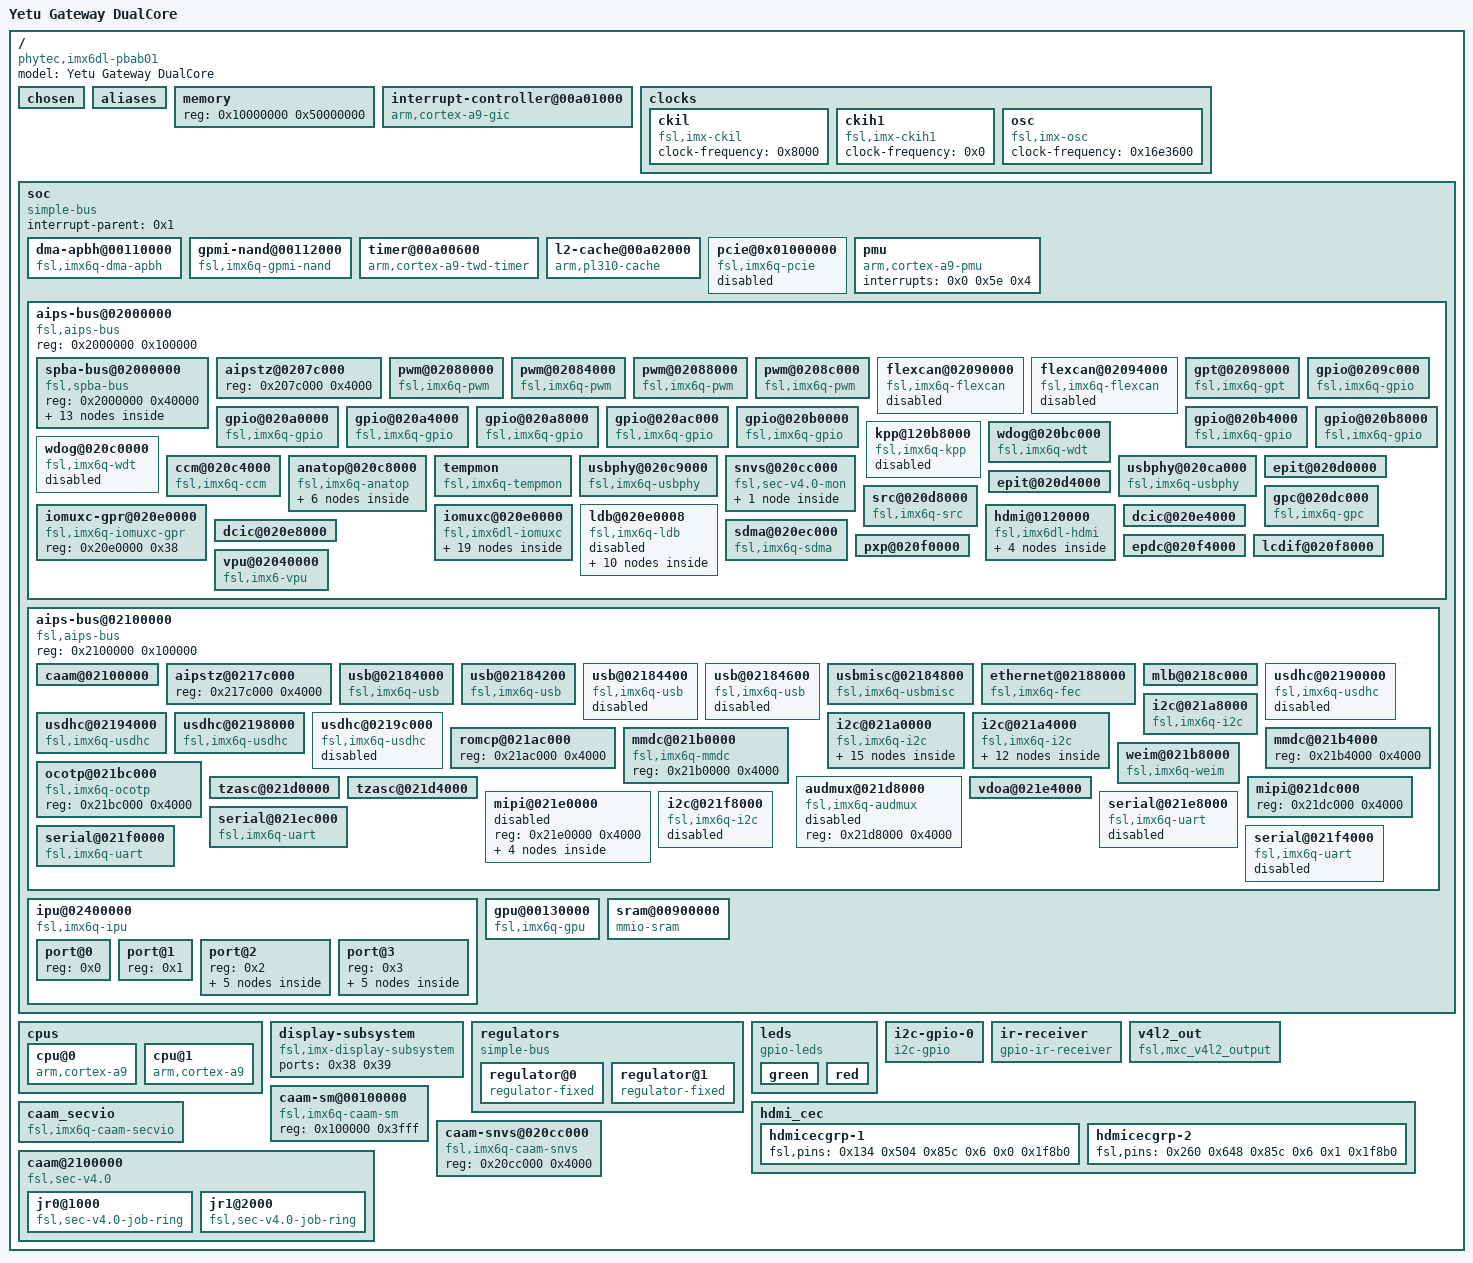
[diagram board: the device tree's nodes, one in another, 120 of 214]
/dts-v1/;

/ {
	#address-cells = <0x1>;
	#size-cells = <0x1>;
	model = "Yetu Gateway DualCore";
	compatible = "phytec,imx6dl-pbab01", "phytec,imx6dl-pfla02", "fsl,imx6dl";

	chosen {
		linux,stdout-path = "/soc/aips-bus@02100000/serial@021f0000";
		bootargs = " cros_debug debug loglevel=7 mem=1024M,0x10000000 drm_kms_helper.edid_firmware=edid/1280x720.bin";
	};

	aliases {
		ethernet0 = "/soc/aips-bus@02100000/ethernet@02188000";
		can0 = "/soc/aips-bus@02000000/flexcan@02090000";
		can1 = "/soc/aips-bus@02000000/flexcan@02094000";
		gpio0 = "/soc/aips-bus@02000000/gpio@0209c000";
		gpio1 = "/soc/aips-bus@02000000/gpio@020a0000";
		gpio2 = "/soc/aips-bus@02000000/gpio@020a4000";
		gpio3 = "/soc/aips-bus@02000000/gpio@020a8000";
		gpio4 = "/soc/aips-bus@02000000/gpio@020ac000";
		gpio5 = "/soc/aips-bus@02000000/gpio@020b0000";
		gpio6 = "/soc/aips-bus@02000000/gpio@020b4000";
		gpio7 = "/soc/aips-bus@02000000/gpio@020b8000";
		i2c0 = "/soc/aips-bus@02100000/i2c@021a0000";
		i2c1 = "/soc/aips-bus@02100000/i2c@021a4000";
		i2c2 = "/soc/aips-bus@02100000/i2c@021a8000";
		mmc0 = "/soc/aips-bus@02100000/usdhc@02190000";
		mmc1 = "/soc/aips-bus@02100000/usdhc@02194000";
		mmc2 = "/soc/aips-bus@02100000/usdhc@02198000";
		mmc3 = "/soc/aips-bus@02100000/usdhc@0219c000";
		serial0 = "/soc/aips-bus@02000000/spba-bus@02000000/serial@02020000";
		serial1 = "/soc/aips-bus@02100000/serial@021e8000";
		serial2 = "/soc/aips-bus@02100000/serial@021ec000";
		serial3 = "/soc/aips-bus@02100000/serial@021f0000";
		serial4 = "/soc/aips-bus@02100000/serial@021f4000";
		spi0 = "/soc/aips-bus@02000000/spba-bus@02000000/ecspi@02008000";
		spi1 = "/soc/aips-bus@02000000/spba-bus@02000000/ecspi@0200c000";
		spi2 = "/soc/aips-bus@02000000/spba-bus@02000000/ecspi@02010000";
		spi3 = "/soc/aips-bus@02000000/spba-bus@02000000/ecspi@02014000";
		usbphy0 = "/soc/aips-bus@02000000/usbphy@020c9000";
		usbphy1 = "/soc/aips-bus@02000000/usbphy@020ca000";
		i2c3 = "/i2c-gpio-0";
	};

	memory {
		device_type = "memory";
		reg = <0x10000000 0x50000000>;
	};

	interrupt-controller@00a01000 {
		compatible = "arm,cortex-a9-gic";
		#interrupt-cells = <0x3>;
		interrupt-controller;
		reg = <0xa01000 0x1000 0xa00100 0x100>;
		linux,phandle = <0x1>;
		phandle = <0x1>;
	};

	clocks {
		#address-cells = <0x1>;
		#size-cells = <0x0>;

		ckil {
			compatible = "fsl,imx-ckil", "fixed-clock";
			#clock-cells = <0x0>;
			clock-frequency = <0x8000>;
		};

		ckih1 {
			compatible = "fsl,imx-ckih1", "fixed-clock";
			#clock-cells = <0x0>;
			clock-frequency = <0x0>;
		};

		osc {
			compatible = "fsl,imx-osc", "fixed-clock";
			#clock-cells = <0x0>;
			clock-frequency = <0x16e3600>;
		};
	};

	soc {
		#address-cells = <0x1>;
		#size-cells = <0x1>;
		compatible = "simple-bus";
		interrupt-parent = <0x1>;
		ranges;

		dma-apbh@00110000 {
			compatible = "fsl,imx6q-dma-apbh", "fsl,imx28-dma-apbh";
			reg = <0x110000 0x2000>;
			interrupts = <0x0 0xd 0x4 0x0 0xd 0x4 0x0 0xd 0x4 0x0 0xd 0x4>;
			interrupt-names = "gpmi0", "gpmi1", "gpmi2", "gpmi3";
			#dma-cells = <0x1>;
			dma-channels = <0x4>;
			clocks = <0x2 0x6a>;
			linux,phandle = <0x3>;
			phandle = <0x3>;
		};

		gpmi-nand@00112000 {
			compatible = "fsl,imx6q-gpmi-nand";
			#address-cells = <0x1>;
			#size-cells = <0x1>;
			reg = <0x112000 0x2000 0x114000 0x2000>;
			reg-names = "gpmi-nand", "bch";
			interrupts = <0x0 0xf 0x4>;
			interrupt-names = "bch";
			clocks = <0x2 0x98 0x2 0x99 0x2 0x97 0x2 0x96 0x2 0x95>;
			clock-names = "gpmi_io", "gpmi_apb", "gpmi_bch", "gpmi_bch_apb", "per1_bch";
			dmas = <0x3 0x0>;
			dma-names = "rx-tx";
			status = "okay";
			pinctrl-names = "default";
			pinctrl-0 = <0x4>;
			nand-on-flash-bbt;
		};

		timer@00a00600 {
			compatible = "arm,cortex-a9-twd-timer";
			reg = <0xa00600 0x20>;
			interrupts = <0x1 0xd 0xf01>;
			clocks = <0x2 0xf>;
		};

		l2-cache@00a02000 {
			compatible = "arm,pl310-cache";
			reg = <0xa02000 0x1000>;
			interrupts = <0x0 0x5c 0x4>;
			cache-unified;
			cache-level = <0x2>;
			arm,tag-latency = <0x4 0x2 0x3>;
			arm,data-latency = <0x4 0x2 0x3>;
			linux,phandle = <0x35>;
			phandle = <0x35>;
		};

		pcie@0x01000000 {
			compatible = "fsl,imx6q-pcie", "snps,dw-pcie";
			reg = <0x1ffc000 0x4000 0x1f00000 0x80000>;
			reg-names = "dbi", "config";
			#address-cells = <0x3>;
			#size-cells = <0x2>;
			device_type = "pci";
			ranges = <0x800 0x0 0x1f00000 0x1f00000 0x0 0x80000 0x81000000 0x0 0x0 0x1f80000 0x0 0x10000 0x82000000 0x0 0x1000000 0x1000000 0x0 0xf00000>;
			num-lanes = <0x1>;
			interrupts = <0x0 0x78 0x4>;
			interrupt-names = "msi";
			#interrupt-cells = <0x1>;
			interrupt-map-mask = <0x0 0x0 0x0 0x7>;
			interrupt-map = <0x0 0x0 0x0 0x1 0x1 0x0 0x7b 0x4 0x0 0x0 0x0 0x2 0x1 0x0 0x7a 0x4 0x0 0x0 0x0 0x3 0x1 0x0 0x79 0x4 0x0 0x0 0x0 0x4 0x1 0x0 0x78 0x4>;
			clocks = <0x2 0x90 0x2 0xce 0x2 0xbd>;
			clock-names = "pcie", "pcie_bus", "pcie_phy";
			status = "disabled";
		};

		pmu {
			compatible = "arm,cortex-a9-pmu";
			interrupts = <0x0 0x5e 0x4>;
		};

		aips-bus@02000000 {
			compatible = "fsl,aips-bus", "simple-bus";
			#address-cells = <0x1>;
			#size-cells = <0x1>;
			reg = <0x2000000 0x100000>;
			ranges;

			spba-bus@02000000 {
				compatible = "fsl,spba-bus", "simple-bus";
				#address-cells = <0x1>;
				#size-cells = <0x1>;
				reg = <0x2000000 0x40000>;
				ranges;

				spdif@02004000 {
					compatible = "fsl,imx35-spdif";
					reg = <0x2004000 0x4000>;
					interrupts = <0x0 0x34 0x4>;
					dmas = <0x5 0xe 0x12 0x0 0x5 0xf 0x12 0x0>;
					dma-names = "rx", "tx";
					clocks = <0x2 0xc5 0x2 0x3 0x2 0xc5 0x2 0x0 0x2 0x0 0x2 0x0 0x2 0x0 0x2 0x0 0x2 0x0>;
					clock-names = "core", "rxtx0", "rxtx1", "rxtx2", "rxtx3", "rxtx4", "rxtx5", "rxtx6", "rxtx7";
					status = "disabled";
				};

				ecspi@02008000 {
					#address-cells = <0x1>;
					#size-cells = <0x0>;
					compatible = "fsl,imx6q-ecspi", "fsl,imx51-ecspi";
					reg = <0x2008000 0x4000>;
					interrupts = <0x0 0x1f 0x4>;
					clocks = <0x2 0x70 0x2 0x70>;
					clock-names = "ipg", "per";
					dmas = <0x5 0x3 0x7 0x1 0x5 0x4 0x7 0x2>;
					dma-names = "rx", "tx";
					status = "disabled";
				};

				ecspi@0200c000 {
					#address-cells = <0x1>;
					#size-cells = <0x0>;
					compatible = "fsl,imx6q-ecspi", "fsl,imx51-ecspi";
					reg = <0x200c000 0x4000>;
					interrupts = <0x0 0x20 0x4>;
					clocks = <0x2 0x71 0x2 0x71>;
					clock-names = "ipg", "per";
					dmas = <0x5 0x5 0x7 0x1 0x5 0x6 0x7 0x2>;
					dma-names = "rx", "tx";
					status = "disabled";
				};

				ecspi@02010000 {
					#address-cells = <0x1>;
					#size-cells = <0x0>;
					compatible = "fsl,imx6q-ecspi", "fsl,imx51-ecspi";
					reg = <0x2010000 0x4000>;
					interrupts = <0x0 0x21 0x4>;
					clocks = <0x2 0x72 0x2 0x72>;
					clock-names = "ipg", "per";
					dmas = <0x5 0x7 0x7 0x1 0x5 0x8 0x7 0x2>;
					dma-names = "rx", "tx";
					status = "okay";
					pinctrl-names = "default";
					pinctrl-0 = <0x6>;
					fsl,spi-num-chipselects = <0x1>;
					cs-gpios = <0x7 0x18 0x0>;

					flash@0 {
						compatible = "m25p80";
						spi-max-frequency = <0x1312d00>;
						reg = <0x0>;
					};
				};

				ecspi@02014000 {
					#address-cells = <0x1>;
					#size-cells = <0x0>;
					compatible = "fsl,imx6q-ecspi", "fsl,imx51-ecspi";
					reg = <0x2014000 0x4000>;
					interrupts = <0x0 0x22 0x4>;
					clocks = <0x2 0x73 0x2 0x73>;
					clock-names = "ipg", "per";
					dmas = <0x5 0x9 0x7 0x1 0x5 0xa 0x7 0x2>;
					dma-names = "rx", "tx";
					status = "disabled";
				};

				serial@02020000 {
					compatible = "fsl,imx6q-uart", "fsl,imx21-uart";
					reg = <0x2020000 0x4000>;
					interrupts = <0x0 0x1a 0x4>;
					clocks = <0x2 0xa0 0x2 0xa1>;
					clock-names = "ipg", "per";
					dmas = <0x5 0x19 0x4 0x0 0x5 0x1a 0x4 0x0>;
					dma-names = "rx", "tx";
					status = "okay";
					pinctrl-names = "default";
					pinctrl-0 = <0x8>;
				};

				esai@02024000 {
					reg = <0x2024000 0x4000>;
					interrupts = <0x0 0x33 0x4>;
				};

				ssi@02028000 {
					#sound-dai-cells = <0x0>;
					compatible = "fsl,imx6q-ssi", "fsl,imx51-ssi";
					reg = <0x2028000 0x4000>;
					interrupts = <0x0 0x2e 0x4>;
					clocks = <0x2 0xb2 0x2 0x9d>;
					clock-names = "ipg", "baud";
					dmas = <0x5 0x25 0x1 0x0 0x5 0x26 0x1 0x0>;
					dma-names = "rx", "tx";
					fsl,fifo-depth = <0xf>;
					status = "disabled";
				};

				ssi@0202c000 {
					#sound-dai-cells = <0x0>;
					compatible = "fsl,imx6q-ssi", "fsl,imx51-ssi";
					reg = <0x202c000 0x4000>;
					interrupts = <0x0 0x2f 0x4>;
					clocks = <0x2 0xb3 0x2 0x9e>;
					clock-names = "ipg", "baud";
					dmas = <0x5 0x29 0x1 0x0 0x5 0x2a 0x1 0x0>;
					dma-names = "rx", "tx";
					fsl,fifo-depth = <0xf>;
					status = "disabled";
				};

				ssi@02030000 {
					#sound-dai-cells = <0x0>;
					compatible = "fsl,imx6q-ssi", "fsl,imx51-ssi";
					reg = <0x2030000 0x4000>;
					interrupts = <0x0 0x30 0x4>;
					clocks = <0x2 0xb4 0x2 0x9f>;
					clock-names = "ipg", "baud";
					dmas = <0x5 0x2d 0x1 0x0 0x5 0x2e 0x1 0x0>;
					dma-names = "rx", "tx";
					fsl,fifo-depth = <0xf>;
					status = "disabled";
				};

				asrc@02034000 {
					reg = <0x2034000 0x4000>;
					interrupts = <0x0 0x32 0x4>;
				};

				spba@0203c000 {
					reg = <0x203c000 0x4000>;
				};
			};

			aipstz@0207c000 {
				reg = <0x207c000 0x4000>;
			};

			pwm@02080000 {
				#pwm-cells = <0x2>;
				compatible = "fsl,imx6q-pwm", "fsl,imx27-pwm";
				reg = <0x2080000 0x4000>;
				interrupts = <0x0 0x53 0x4>;
				clocks = <0x2 0x3e 0x2 0x91>;
				clock-names = "ipg", "per";
			};

			pwm@02084000 {
				#pwm-cells = <0x2>;
				compatible = "fsl,imx6q-pwm", "fsl,imx27-pwm";
				reg = <0x2084000 0x4000>;
				interrupts = <0x0 0x54 0x4>;
				clocks = <0x2 0x3e 0x2 0x92>;
				clock-names = "ipg", "per";
			};

			pwm@02088000 {
				#pwm-cells = <0x2>;
				compatible = "fsl,imx6q-pwm", "fsl,imx27-pwm";
				reg = <0x2088000 0x4000>;
				interrupts = <0x0 0x55 0x4>;
				clocks = <0x2 0x3e 0x2 0x93>;
				clock-names = "ipg", "per";
			};

			pwm@0208c000 {
				#pwm-cells = <0x2>;
				compatible = "fsl,imx6q-pwm", "fsl,imx27-pwm";
				reg = <0x208c000 0x4000>;
				interrupts = <0x0 0x56 0x4>;
				clocks = <0x2 0x3e 0x2 0x94>;
				clock-names = "ipg", "per";
			};

			flexcan@02090000 {
				compatible = "fsl,imx6q-flexcan";
				reg = <0x2090000 0x4000>;
				interrupts = <0x0 0x6e 0x4>;
				clocks = <0x2 0x6c 0x2 0x6d>;
				clock-names = "ipg", "per";
				status = "disabled";
			};

			flexcan@02094000 {
				compatible = "fsl,imx6q-flexcan";
				reg = <0x2094000 0x4000>;
				interrupts = <0x0 0x6f 0x4>;
				clocks = <0x2 0x6e 0x2 0x6f>;
				clock-names = "ipg", "per";
				status = "disabled";
			};

			gpt@02098000 {
				compatible = "fsl,imx6q-gpt", "fsl,imx31-gpt";
				reg = <0x2098000 0x4000>;
				interrupts = <0x0 0x37 0x4>;
				clocks = <0x2 0x77 0x2 0x78 0x2 0xed>;
				clock-names = "ipg", "per", "osc_per";
			};

			gpio@0209c000 {
				compatible = "fsl,imx6q-gpio", "fsl,imx35-gpio";
				reg = <0x209c000 0x4000>;
				interrupts = <0x0 0x42 0x4 0x0 0x43 0x4>;
				gpio-controller;
				#gpio-cells = <0x2>;
				interrupt-controller;
				#interrupt-cells = <0x2>;
				linux,phandle = <0x22>;
				phandle = <0x22>;
			};

			gpio@020a0000 {
				compatible = "fsl,imx6q-gpio", "fsl,imx35-gpio";
				reg = <0x20a0000 0x4000>;
				interrupts = <0x0 0x44 0x4 0x0 0x45 0x4>;
				gpio-controller;
				#gpio-cells = <0x2>;
				interrupt-controller;
				#interrupt-cells = <0x2>;
				linux,phandle = <0x3a>;
				phandle = <0x3a>;
			};

			gpio@020a4000 {
				compatible = "fsl,imx6q-gpio", "fsl,imx35-gpio";
				reg = <0x20a4000 0x4000>;
				interrupts = <0x0 0x46 0x4 0x0 0x47 0x4>;
				gpio-controller;
				#gpio-cells = <0x2>;
				interrupt-controller;
				#interrupt-cells = <0x2>;
				linux,phandle = <0x1f>;
				phandle = <0x1f>;
			};

			gpio@020a8000 {
				compatible = "fsl,imx6q-gpio", "fsl,imx35-gpio";
				reg = <0x20a8000 0x4000>;
				interrupts = <0x0 0x48 0x4 0x0 0x49 0x4>;
				gpio-controller;
				#gpio-cells = <0x2>;
				interrupt-controller;
				#interrupt-cells = <0x2>;
				linux,phandle = <0x7>;
				phandle = <0x7>;
			};

			gpio@020ac000 {
				compatible = "fsl,imx6q-gpio", "fsl,imx35-gpio";
				reg = <0x20ac000 0x4000>;
				interrupts = <0x0 0x4a 0x4 0x0 0x4b 0x4>;
				gpio-controller;
				#gpio-cells = <0x2>;
				interrupt-controller;
				#interrupt-cells = <0x2>;
			};

			gpio@020b0000 {
				compatible = "fsl,imx6q-gpio", "fsl,imx35-gpio";
				reg = <0x20b0000 0x4000>;
				interrupts = <0x0 0x4c 0x4 0x0 0x4d 0x4>;
				gpio-controller;
				#gpio-cells = <0x2>;
				interrupt-controller;
				#interrupt-cells = <0x2>;
			};

			gpio@020b4000 {
				compatible = "fsl,imx6q-gpio", "fsl,imx35-gpio";
				reg = <0x20b4000 0x4000>;
				interrupts = <0x0 0x4e 0x4 0x0 0x4f 0x4>;
				gpio-controller;
				#gpio-cells = <0x2>;
				interrupt-controller;
				#interrupt-cells = <0x2>;
				linux,phandle = <0x27>;
				phandle = <0x27>;
			};

			gpio@020b8000 {
				compatible = "fsl,imx6q-gpio", "fsl,imx35-gpio";
				reg = <0x20b8000 0x4000>;
				gpio-controller;
				#gpio-cells = <0x2>;
			};

			kpp@120b8000 {
				compatible = "fsl,imx6q-kpp", "fsl,imx21-kpp";
				reg = <0x120b8000 0x4000>;
				interrupts = <0x0 0x52 0x4>;
				clocks = <0x2 0x3e>;
				status = "disabled";
			};

			wdog@020bc000 {
				compatible = "fsl,imx6q-wdt", "fsl,imx21-wdt";
				reg = <0x20bc000 0x4000>;
				interrupts = <0x0 0x50 0x4>;
				clocks = <0x2 0x0>;
			};

			wdog@020c0000 {
				compatible = "fsl,imx6q-wdt", "fsl,imx21-wdt";
				reg = <0x20c0000 0x4000>;
				interrupts = <0x0 0x51 0x4>;
				clocks = <0x2 0x0>;
				status = "disabled";
			};

			ccm@020c4000 {
				compatible = "fsl,imx6q-ccm";
				reg = <0x20c4000 0x4000>;
				interrupts = <0x0 0x57 0x4 0x0 0x58 0x4>;
				#clock-cells = <0x1>;
				linux,phandle = <0x2>;
				phandle = <0x2>;
			};

			anatop@020c8000 {
				compatible = "fsl,imx6q-anatop", "syscon", "simple-bus";
				reg = <0x20c8000 0x1000>;
				interrupts = <0x0 0x31 0x4 0x0 0x36 0x4 0x0 0x7f 0x4>;
				linux,phandle = <0x9>;
				phandle = <0x9>;

				regulator-1p1@110 {
					compatible = "fsl,anatop-regulator";
					regulator-name = "vdd1p1";
					regulator-min-microvolt = <0xc3500>;
					regulator-max-microvolt = <0x14fb18>;
					regulator-always-on;
					anatop-reg-offset = <0x110>;
					anatop-vol-bit-shift = <0x8>;
					anatop-vol-bit-width = <0x5>;
					anatop-min-bit-val = <0x4>;
					anatop-min-voltage = <0xc3500>;
					anatop-max-voltage = <0x14fb18>;
				};

				regulator-3p0@120 {
					compatible = "fsl,anatop-regulator";
					regulator-name = "vdd3p0";
					regulator-min-microvolt = <0x2ab980>;
					regulator-max-microvolt = <0x3010b0>;
					regulator-always-on;
					anatop-reg-offset = <0x120>;
					anatop-vol-bit-shift = <0x8>;
					anatop-vol-bit-width = <0x5>;
					anatop-min-bit-val = <0x0>;
					anatop-min-voltage = <0x280de8>;
					anatop-max-voltage = <0x33e140>;
				};

				regulator-2p5@130 {
					compatible = "fsl,anatop-regulator";
					regulator-name = "vdd2p5";
					regulator-min-microvolt = <0x1e8480>;
					regulator-max-microvolt = <0x29f630>;
					regulator-always-on;
					anatop-reg-offset = <0x130>;
					anatop-vol-bit-shift = <0x8>;
					anatop-vol-bit-width = <0x5>;
					anatop-min-bit-val = <0x0>;
					anatop-min-voltage = <0x1e8480>;
					anatop-max-voltage = <0x29f630>;
				};

				regulator-vddcore@140 {
					compatible = "fsl,anatop-regulator";
					regulator-name = "vddarm";
					regulator-min-microvolt = <0xb1008>;
					regulator-max-microvolt = <0x162010>;
					regulator-always-on;
					anatop-reg-offset = <0x140>;
					anatop-vol-bit-shift = <0x0>;
					anatop-vol-bit-width = <0x5>;
					anatop-delay-reg-offset = <0x170>;
					anatop-delay-bit-shift = <0x18>;
					anatop-delay-bit-width = <0x2>;
					anatop-min-bit-val = <0x1>;
					anatop-min-voltage = <0xb1008>;
					anatop-max-voltage = <0x162010>;
					linux,phandle = <0x36>;
					phandle = <0x36>;
				};

				regulator-vddpu@140 {
					compatible = "fsl,anatop-regulator";
					regulator-name = "vddpu";
					regulator-min-microvolt = <0xb1008>;
					regulator-max-microvolt = <0x162010>;
					regulator-always-on;
					anatop-reg-offset = <0x140>;
					anatop-vol-bit-shift = <0x9>;
					anatop-vol-bit-width = <0x5>;
					anatop-delay-reg-offset = <0x170>;
					anatop-delay-bit-shift = <0x1a>;
					anatop-delay-bit-width = <0x2>;
					anatop-min-bit-val = <0x1>;
					anatop-min-voltage = <0xb1008>;
					anatop-max-voltage = <0x162010>;
					linux,phandle = <0x16>;
					phandle = <0x16>;
				};

				regulator-vddsoc@140 {
					compatible = "fsl,anatop-regulator";
					regulator-name = "vddsoc";
					regulator-min-microvolt = <0xb1008>;
					regulator-max-microvolt = <0x162010>;
					regulator-always-on;
					anatop-reg-offset = <0x140>;
					anatop-vol-bit-shift = <0x12>;
					anatop-vol-bit-width = <0x5>;
					anatop-delay-reg-offset = <0x170>;
					anatop-delay-bit-shift = <0x1c>;
					anatop-delay-bit-width = <0x2>;
					anatop-min-bit-val = <0x1>;
					anatop-min-voltage = <0xb1008>;
					anatop-max-voltage = <0x162010>;
					linux,phandle = <0x37>;
					phandle = <0x37>;
				};
			};

			tempmon {
				compatible = "fsl,imx6q-tempmon";
				interrupts = <0x0 0x31 0x4>;
				fsl,tempmon = <0x9>;
				fsl,tempmon-data = <0xa>;
				clocks = <0x2 0xac>;
			};

			usbphy@020c9000 {
				compatible = "fsl,imx6q-usbphy", "fsl,imx23-usbphy";
				reg = <0x20c9000 0x1000>;
				interrupts = <0x0 0x2c 0x4>;
				clocks = <0x2 0xb6>;
				fsl,anatop = <0x9>;
				linux,phandle = <0x17>;
				phandle = <0x17>;
			};

			usbphy@020ca000 {
				compatible = "fsl,imx6q-usbphy", "fsl,imx23-usbphy";
				reg = <0x20ca000 0x1000>;
				interrupts = <0x0 0x2d 0x4>;
				clocks = <0x2 0xb7>;
				fsl,anatop = <0x9>;
				linux,phandle = <0x1b>;
				phandle = <0x1b>;
			};

			snvs@020cc000 {
				compatible = "fsl,sec-v4.0-mon", "simple-bus";
				#address-cells = <0x1>;
				#size-cells = <0x1>;
				ranges = <0x0 0x20cc000 0x4000>;

				snvs-rtc-lp@34 {
					compatible = "fsl,sec-v4.0-mon-rtc-lp";
					reg = <0x34 0x58>;
					interrupts = <0x0 0x13 0x4 0x0 0x14 0x4>;
				};
			};

			epit@020d0000 {
				reg = <0x20d0000 0x4000>;
				interrupts = <0x0 0x38 0x4>;
			};

			epit@020d4000 {
				reg = <0x20d4000 0x4000>;
				interrupts = <0x0 0x39 0x4>;
			};

			src@020d8000 {
				compatible = "fsl,imx6q-src", "fsl,imx51-src";
				reg = <0x20d8000 0x4000>;
				interrupts = <0x0 0x5b 0x4 0x0 0x60 0x4>;
				#reset-cells = <0x1>;
				linux,phandle = <0x15>;
				phandle = <0x15>;
			};

			gpc@020dc000 {
				compatible = "fsl,imx6q-gpc";
				reg = <0x20dc000 0x4000>;
				interrupts = <0x0 0x59 0x4 0x0 0x5a 0x4>;
			};

			iomuxc-gpr@020e0000 {
				compatible = "fsl,imx6q-iomuxc-gpr", "syscon";
				reg = <0x20e0000 0x38>;
				linux,phandle = <0xc>;
				phandle = <0xc>;
			};

			iomuxc@020e0000 {
				compatible = "fsl,imx6dl-iomuxc";
				reg = <0x20e0000 0x4000>;
				pinctrl-names = "default";
				pinctrl-0 = <0xb>;

				imx6q-phytec-pfla02 {

					hdmicecgrp {
						fsl,pins = <0x134 0x504 0x85c 0x6 0x0 0x1f8b0>;
						linux,phandle = <0x11>;
						phandle = <0x11>;
					};

					pinctrli2cgpiogrp {
						fsl,pins = <0x264 0x64c 0x0 0x5 0x0 0x80000000 0x250 0x638 0x0 0x5 0x0 0x80000000>;
						linux,phandle = <0x3b>;
						phandle = <0x3b>;
					};

					hoggrp {
						fsl,pins = <0x160 0x530 0x0 0x5 0x0 0x80000000 0xf4 0x408 0x0 0x5 0x0 0x80000000 0xa0 0x3b4 0x0 0x5 0x0 0x80000000 0x204 0x5d4 0x0 0x5 0x0 0x80000000 0x1d0 0x5a0 0x0 0x5 0x0 0x80000000 0x21c 0x5ec 0x0 0x5 0x0 0x1b0b0 0xa8 0x3bc 0x0 0x5 0x0 0x1b0b0 0x228 0x5f8 0x0 0x5 0x0 0x80000000>;
						linux,phandle = <0xb>;
						phandle = <0xb>;
					};

					ecspi3grp {
						fsl,pins = <0xe0 0x3f4 0x0 0x2 0x0 0x100b1 0xb4 0x3c8 0x0 0x2 0x0 0x100b1 0xb0 0x3c4 0x0 0x2 0x0 0x100b1>;
						linux,phandle = <0x6>;
						phandle = <0x6>;
					};

					enetgrp {
						fsl,pins = <0x1ec 0x5bc 0x810 0x1 0x0 0x1b0b0 0x1e8 0x5b8 0x0 0x1 0x0 0x1b0b0 0x2d8 0x6c0 0x0 0x1 0x0 0x1b0b0 0x2c4 0x6ac 0x0 0x1 0x0 0x1b0b0 0x2c8 0x6b0 0x0 0x1 0x0 0x1b0b0 0x2cc 0x6b4 0x0 0x1 0x0 0x1b0b0 0x2d0 0x6b8 0x0 0x1 0x0 0x1b0b0 0x2d4 0x6bc 0x0 0x1 0x0 0x1b0b0 0x1f0 0x5c0 0x0 0x1 0x0 0x1b0b0 0x2c0 0x6a8 0x814 0x1 0x1 0x1b0b0 0x2ac 0x694 0x818 0x1 0x1 0x1b0b0 0x2b0 0x698 0x81c 0x1 0x1 0x1b0b0 0x2b4 0x69c 0x820 0x1 0x1 0x1b0b0 0x2b8 0x6a0 0x824 0x1 0x1 0x1b0b0 0x2bc 0x6a4 0x828 0x1 0x1 0x1b0b0 0x200 0x5d0 0x0 0x1 0x0 0x1b0b0>;
						linux,phandle = <0x1e>;
						phandle = <0x1e>;
					};

					gpminandgrp {
						fsl,pins = <0x270 0x658 0x0 0x0 0x0 0xb0b1 0x26c 0x654 0x0 0x0 0x0 0xb0b1 0x2a8 0x690 0x0 0x0 0x0 0xb0b1 0x2a4 0x68c 0x0 0x0 0x0 0xb000 0x274 0x65c 0x0 0x0 0x0 0xb0b1 0x278 0x660 0x0 0x0 0x0 0xb0b1 0x33c 0x724 0x0 0x1 0x0 0xb0b1 0x338 0x720 0x0 0x1 0x0 0xb0b1 0x284 0x66c 0x0 0x0 0x0 0xb0b1 0x288 0x670 0x0 0x0 0x0 0xb0b1 0x28c 0x674 0x0 0x0 0x0 0xb0b1 0x290 0x678 0x0 0x0 0x0 0xb0b1 0x294 0x67c 0x0 0x0 0x0 0xb0b1 0x298 0x680 0x0 0x0 0x0 0xb0b1 0x29c 0x684 0x0 0x0 0x0 0xb0b1 0x2a0 0x688 0x0 0x0 0x0 0xb0b1 0x340 0x728 0x0 0x2 0x0 0xb1>;
						linux,phandle = <0x4>;
						phandle = <0x4>;
					};

					i2c1grp {
						fsl,pins = <0x158 0x528 0x868 0x6 0x1 0x4001b8b1 0x174 0x544 0x86c 0x1 0x1 0x4001b8b1>;
						linux,phandle = <0x25>;
						phandle = <0x25>;
					};

					i2c2grp {
						fsl,pins = <0x1cc 0x59c 0x870 0x6 0x0 0x4001b8b1 0x144 0x514 0x874 0x6 0x0 0x4001b8b1>;
						linux,phandle = <0x26>;
						phandle = <0x26>;
					};

					i2c3grp {
						fsl,pins = <0x148 0x518 0x878 0x6 0x0 0x4001b8b1 0x14c 0x51c 0x87c 0x6 0x0 0x4001b8b1>;
						linux,phandle = <0x28>;
						phandle = <0x28>;
					};

					uart3grp {
						fsl,pins = <0x164 0x534 0x0 0x2 0x0 0x1b0b1 0x168 0x538 0x90c 0x2 0x1 0x1b0b1 0x17c 0x54c 0x908 0x4 0x1 0x1b0b1 0x180 0x550 0x0 0x4 0x0 0x1b0b1>;
						linux,phandle = <0x2b>;
						phandle = <0x2b>;
					};

					uart4grp {
						fsl,pins = <0x244 0x62c 0x0 0x4 0x0 0x1b0b1 0x258 0x640 0x914 0x4 0x3 0x1b0b1>;
						linux,phandle = <0x2c>;
						phandle = <0x2c>;
					};

					usbh1grp {
						fsl,pins = <0x20c 0x5dc 0x0 0x6 0x0 0x80000000>;
						linux,phandle = <0x1d>;
						phandle = <0x1d>;
					};

					usbotggrp {
						fsl,pins = <0x210 0x5e0 0x790 0x3 0x1 0x17059 0x254 0x63c 0x920 0x2 0x1 0x1b0b0 0x268 0x650 0x0 0x5 0x0 0x80000000>;
						linux,phandle = <0x1a>;
						phandle = <0x1a>;
					};

					usdhc2grp {
						fsl,pins = <0x2f8 0x6e0 0x0 0x0 0x0 0x17059 0x2f4 0x6dc 0x930 0x0 0x1 0x10059 0x2fc 0x6e4 0x0 0x0 0x0 0x17059 0x300 0x6e8 0x0 0x0 0x0 0x17059 0x304 0x6ec 0x0 0x0 0x0 0x17059 0x308 0x6f0 0x0 0x0 0x0 0x17059>;
						linux,phandle = <0x21>;
						phandle = <0x21>;
					};

					usdhc3grp {
						fsl,pins = <0x310 0x6f8 0x0 0x0 0x0 0x17059 0x30c 0x6f4 0x934 0x0 0x1 0x10059 0x314 0x6fc 0x0 0x0 0x0 0x17059 0x318 0x700 0x0 0x0 0x0 0x17059 0x31c 0x704 0x0 0x0 0x0 0x17059 0x320 0x708 0x0 0x0 0x0 0x17059>;
						linux,phandle = <0x23>;
						phandle = <0x23>;
					};

					usdhc3cdwp {
						fsl,pins = <0x1f8 0x5c8 0x0 0x5 0x0 0x80000000 0x208 0x5d8 0x0 0x5 0x0 0x80000000>;
						linux,phandle = <0x24>;
						phandle = <0x24>;
					};
				};

				uart1grp {
					fsl,pins = <0x330 0x718 0x0 0x1 0x0 0x1b0b1 0x32c 0x714 0x8fc 0x1 0x2 0x1b0b1>;
					linux,phandle = <0x8>;
					phandle = <0x8>;
				};

				gpio_ir {
					fsl,pins = <0x324 0x70c 0x0 0x5 0x0 0x80000000>;
					linux,phandle = <0x3c>;
					phandle = <0x3c>;
				};
			};

			ldb@020e0008 {
				#address-cells = <0x1>;
				#size-cells = <0x0>;
				compatible = "fsl,imx6q-ldb", "fsl,imx53-ldb";
				gpr = <0xc>;
				status = "disabled";
				clocks = <0x2 0x21 0x2 0x22 0x2 0x27 0x2 0x28 0x2 0x87 0x2 0x88>;
				clock-names = "di0_pll", "di1_pll", "di0_sel", "di1_sel", "di0", "di1";

				lvds-channel@0 {
					#address-cells = <0x1>;
					#size-cells = <0x0>;
					reg = <0x0>;
					status = "disabled";

					port@0 {
						reg = <0x0>;

						endpoint {
							remote-endpoint = <0xd>;
							linux,phandle = <0x2f>;
							phandle = <0x2f>;
						};
					};

					port@1 {
						reg = <0x1>;

						endpoint {
							remote-endpoint = <0xe>;
							linux,phandle = <0x33>;
							phandle = <0x33>;
						};
					};
				};

				lvds-channel@1 {
					#address-cells = <0x1>;
					#size-cells = <0x0>;
					reg = <0x1>;
					status = "disabled";

					port@0 {
						reg = <0x0>;

						endpoint {
							remote-endpoint = <0xf>;
							linux,phandle = <0x30>;
							phandle = <0x30>;
						};
					};

					port@1 {
						reg = <0x1>;

						endpoint {
							remote-endpoint = <0x10>;
							linux,phandle = <0x34>;
							phandle = <0x34>;
						};
					};
				};
			};

			hdmi@0120000 {
				#address-cells = <0x1>;
				#size-cells = <0x0>;
				reg = <0x120000 0x9000>;
				interrupts = <0x0 0x73 0x4>;
				gpr = <0xc>;
				clocks = <0x2 0x7b 0x2 0x7c>;
				clock-names = "iahb", "isfr";
				status = "okay";
				compatible = "fsl,imx6dl-hdmi";
				pinctrl-names = "default";
				pinctrl-0 = <0x11>;
				ddc-i2c-bus = <0x12>;

				port@0 {
					reg = <0x0>;

					endpoint {
						remote-endpoint = <0x13>;
						linux,phandle = <0x2d>;
						phandle = <0x2d>;
					};
				};

				port@1 {
					reg = <0x1>;

					endpoint {
						remote-endpoint = <0x14>;
						linux,phandle = <0x31>;
						phandle = <0x31>;
					};
				};
			};

			dcic@020e4000 {
				reg = <0x20e4000 0x4000>;
				interrupts = <0x0 0x7c 0x4>;
			};

			dcic@020e8000 {
				reg = <0x20e8000 0x4000>;
				interrupts = <0x0 0x7d 0x4>;
			};

			sdma@020ec000 {
				compatible = "fsl,imx6q-sdma", "fsl,imx35-sdma";
				reg = <0x20ec000 0x4000>;
				interrupts = <0x0 0x2 0x4>;
				clocks = <0x2 0x9b 0x2 0x9b>;
				clock-names = "ipg", "ahb";
				#dma-cells = <0x3>;
				fsl,sdma-ram-script-name = "imx/sdma/sdma-imx6q.bin";
				linux,phandle = <0x5>;
				phandle = <0x5>;
			};

			pxp@020f0000 {
				reg = <0x20f0000 0x4000>;
				interrupts = <0x0 0x62 0x4>;
			};

			epdc@020f4000 {
				reg = <0x20f4000 0x4000>;
				interrupts = <0x0 0x61 0x4>;
			};

			lcdif@020f8000 {
				reg = <0x20f8000 0x4000>;
				interrupts = <0x0 0x27 0x4>;
			};

			vpu@02040000 {
				compatible = "fsl,imx6-vpu";
				reg = <0x2040000 0x3c000>;
				reg-names = "vpu_regs";
				interrupts = <0x0 0x3 0x1 0x0 0xc 0x4>;
				interrupt-names = "vpu_jpu_irq", "vpu_ipi_irq";
				clocks = <0x2 0xa8 0x2 0x8c 0x2 0x8e>;
				clock-names = "vpu_clk", "mmdc_ch0_axi", "ocram";
				resets = <0x15 0x1>;
				pu-supply = <0x16>;
				status = "okay";
			};
		};

		aips-bus@02100000 {
			compatible = "fsl,aips-bus", "simple-bus";
			#address-cells = <0x1>;
			#size-cells = <0x1>;
			reg = <0x2100000 0x100000>;
			ranges;

			caam@02100000 {
				reg = <0x2100000 0x40000>;
				interrupts = <0x0 0x69 0x4 0x0 0x6a 0x4>;
			};

			aipstz@0217c000 {
				reg = <0x217c000 0x4000>;
			};

			usb@02184000 {
				compatible = "fsl,imx6q-usb", "fsl,imx27-usb";
				reg = <0x2184000 0x200>;
				interrupts = <0x0 0x2b 0x4>;
				clocks = <0x2 0xa2>;
				fsl,usbphy = <0x17>;
				fsl,usbmisc = <0x18 0x0>;
				status = "okay";
				vbus-supply = <0x19>;
				pinctrl-names = "default";
				pinctrl-0 = <0x1a>;
				disable-over-current;
			};

			usb@02184200 {
				compatible = "fsl,imx6q-usb", "fsl,imx27-usb";
				reg = <0x2184200 0x200>;
				interrupts = <0x0 0x28 0x4>;
				clocks = <0x2 0xa2>;
				fsl,usbphy = <0x1b>;
				fsl,usbmisc = <0x18 0x1>;
				status = "okay";
				vbus-supply = <0x1c>;
				pinctrl-names = "default";
				pinctrl-0 = <0x1d>;
			};

			usb@02184400 {
				compatible = "fsl,imx6q-usb", "fsl,imx27-usb";
				reg = <0x2184400 0x200>;
				interrupts = <0x0 0x29 0x4>;
				clocks = <0x2 0xa2>;
				fsl,usbmisc = <0x18 0x2>;
				status = "disabled";
			};

			usb@02184600 {
				compatible = "fsl,imx6q-usb", "fsl,imx27-usb";
				reg = <0x2184600 0x200>;
				interrupts = <0x0 0x2a 0x4>;
				clocks = <0x2 0xa2>;
				fsl,usbmisc = <0x18 0x3>;
				status = "disabled";
			};

			usbmisc@02184800 {
				#index-cells = <0x1>;
				compatible = "fsl,imx6q-usbmisc";
				reg = <0x2184800 0x200>;
				clocks = <0x2 0xa2>;
				linux,phandle = <0x18>;
				phandle = <0x18>;
			};

			ethernet@02188000 {
				compatible = "fsl,imx6q-fec";
				reg = <0x2188000 0x4000>;
				interrupts-extended = <0x1 0x0 0x76 0x4 0x1 0x0 0x77 0x4>;
				clocks = <0x2 0x75 0x2 0x75 0x2 0xbe>;
				clock-names = "ipg", "ahb", "ptp";
				status = "okay";
				pinctrl-names = "default";
				pinctrl-0 = <0x1e>;
				phy-mode = "rgmii";
				phy-reset-gpios = <0x1f 0x17 0x1>;
				phy-supply = <0x20>;
			};

			mlb@0218c000 {
				reg = <0x218c000 0x4000>;
				interrupts = <0x0 0x35 0x4 0x0 0x75 0x4 0x0 0x7e 0x4>;
			};

			usdhc@02190000 {
				compatible = "fsl,imx6q-usdhc";
				reg = <0x2190000 0x4000>;
				interrupts = <0x0 0x16 0x4>;
				clocks = <0x2 0xa3 0x2 0xa3 0x2 0xa3>;
				clock-names = "ipg", "ahb", "per";
				bus-width = <0x4>;
				status = "disabled";
			};

			usdhc@02194000 {
				compatible = "fsl,imx6q-usdhc";
				reg = <0x2194000 0x4000>;
				interrupts = <0x0 0x17 0x4>;
				clocks = <0x2 0xa4 0x2 0xa4 0x2 0xa4>;
				clock-names = "ipg", "ahb", "per";
				bus-width = <0x4>;
				status = "okay";
				pinctrl-names = "default";
				pinctrl-0 = <0x21>;
				cd-gpios = <0x22 0x4 0x0>;
				wp-gpios = <0x22 0x2 0x0>;
			};

			usdhc@02198000 {
				compatible = "fsl,imx6q-usdhc";
				reg = <0x2198000 0x4000>;
				interrupts = <0x0 0x18 0x4>;
				clocks = <0x2 0xa5 0x2 0xa5 0x2 0xa5>;
				clock-names = "ipg", "ahb", "per";
				bus-width = <0x4>;
				status = "okay";
				pinctrl-names = "default";
				pinctrl-0 = <0x23 0x24>;
				cd-gpios = <0x22 0x1b 0x0>;
				wp-gpios = <0x22 0x1d 0x0>;
			};

			usdhc@0219c000 {
				compatible = "fsl,imx6q-usdhc";
				reg = <0x219c000 0x4000>;
				interrupts = <0x0 0x19 0x4>;
				clocks = <0x2 0xa6 0x2 0xa6 0x2 0xa6>;
				clock-names = "ipg", "ahb", "per";
				bus-width = <0x4>;
				status = "disabled";
			};

			i2c@021a0000 {
				#address-cells = <0x1>;
				#size-cells = <0x0>;
				compatible = "fsl,imx6q-i2c", "fsl,imx21-i2c";
				reg = <0x21a0000 0x4000>;
				interrupts = <0x0 0x24 0x4>;
				clocks = <0x2 0x7d>;
				status = "okay";
				pinctrl-names = "default";
				pinctrl-0 = <0x25>;

				eeprom@50 {
					compatible = "atmel,24c32";
					reg = <0x50>;
				};

				pmic@58 {
					compatible = "dlg,da9063";
					reg = <0x58>;
					interrupt-parent = <0x7>;
					interrupts = <0x11 0x8>;

					regulators {

						bcore1 {
							regulator-min-microvolt = <0xb2390>;
							regulator-max-microvolt = <0x150ea0>;
							regulator-always-on;
						};

						bcore2 {
							regulator-min-microvolt = <0xb2390>;
							regulator-max-microvolt = <0x150ea0>;
							regulator-always-on;
						};

						bpro {
							regulator-min-microvolt = <0x16e360>;
							regulator-max-microvolt = <0x16e360>;
							regulator-always-on;
						};

						bperi {
							regulator-min-microvolt = <0x325aa0>;
							regulator-max-microvolt = <0x325aa0>;
							regulator-always-on;
						};

						bmem {
							regulator-min-microvolt = <0x325aa0>;
							regulator-max-microvolt = <0x325aa0>;
							regulator-always-on;
						};

						bio {
							regulator-min-microvolt = <0x124f80>;
							regulator-max-microvolt = <0x124f80>;
							regulator-always-on;
						};

						ldo4 {
							regulator-min-microvolt = <0x2625a0>;
							regulator-max-microvolt = <0x2625a0>;
							regulator-always-on;
							linux,phandle = <0x20>;
							phandle = <0x20>;
						};

						ldo5 {
							regulator-min-microvolt = <0x2dc6c0>;
							regulator-max-microvolt = <0x2dc6c0>;
							regulator-always-on;
						};

						ldo6 {
							regulator-min-microvolt = <0x325aa0>;
							regulator-max-microvolt = <0x325aa0>;
							regulator-always-on;
						};

						ldo9 {
							regulator-min-microvolt = <0x325aa0>;
							regulator-max-microvolt = <0x325aa0>;
						};

						ldo10 {
							regulator-min-microvolt = <0x325aa0>;
							regulator-max-microvolt = <0x325aa0>;
						};

						ldo11 {
							regulator-min-microvolt = <0x2dc6c0>;
							regulator-max-microvolt = <0x2dc6c0>;
							regulator-always-on;
						};
					};
				};
			};

			i2c@021a4000 {
				#address-cells = <0x1>;
				#size-cells = <0x0>;
				compatible = "fsl,imx6q-i2c", "fsl,imx21-i2c";
				reg = <0x21a4000 0x4000>;
				interrupts = <0x0 0x25 0x4>;
				clocks = <0x2 0x7e>;
				status = "okay";
				pinctrl-names = "default";
				pinctrl-0 = <0x26>;
				clock-frequency = <0x186a0>;

				tlv320@18 {
					compatible = "ti,tlv320aic3x";
					reg = <0x18>;
				};

				stmpe@41 {
					compatible = "st,stmpe811";
					reg = <0x41>;
				};

				rtc@51 {
					compatible = "nxp,rtc8564";
					reg = <0x51>;
				};

				adc@64 {
					compatible = "maxim,max1037";
					reg = <0x64>;
				};

				tpm@20 {
					compatible = "infineon,slb9645tt";
					reg = <0x20>;
				};

				leds@60 {
					compatible = "nxp,pca9531";
					led-controller;
					#address-cells = <0x1>;
					#size-cells = <0x0>;
					reg = <0x60>;
					gpio = <0x27 0xd 0x0>;

					channel1red@7 {
						label = "channel1-red";
						reg = <0x7>;
					};

					channel1green@6 {
						label = "channel1-green";
						reg = <0x6>;
					};

					channel1blue@5 {
						label = "channel1-blue";
						reg = <0x5>;
					};

					channel2red@3 {
						label = "channel2-red";
						reg = <0x3>;
					};

					channel2green@2 {
						label = "channel2-green";
						reg = <0x2>;
					};

					channel2blue@1 {
						label = "channel2-blue";
						reg = <0x1>;
					};
				};
			};

			i2c@021a8000 {
				#address-cells = <0x1>;
				#size-cells = <0x0>;
				compatible = "fsl,imx6q-i2c", "fsl,imx21-i2c";
				reg = <0x21a8000 0x4000>;
				interrupts = <0x0 0x26 0x4>;
				clocks = <0x2 0x7f>;
				status = "okay";
				pinctrl-names = "default";
				pinctrl-0 = <0x28>;
				clock-frequency = <0x186a0>;
			};

			romcp@021ac000 {
				reg = <0x21ac000 0x4000>;
			};

			mmdc@021b0000 {
				compatible = "fsl,imx6q-mmdc";
				reg = <0x21b0000 0x4000>;
			};

			mmdc@021b4000 {
				reg = <0x21b4000 0x4000>;
			};

			weim@021b8000 {
				compatible = "fsl,imx6q-weim";
				reg = <0x21b8000 0x4000>;
				interrupts = <0x0 0xe 0x4>;
				clocks = <0x2 0xc4>;
			};

			ocotp@021bc000 {
				compatible = "fsl,imx6q-ocotp", "syscon";
				reg = <0x21bc000 0x4000>;
				linux,phandle = <0xa>;
				phandle = <0xa>;
			};

			tzasc@021d0000 {
				reg = <0x21d0000 0x4000>;
				interrupts = <0x0 0x6c 0x4>;
			};

			tzasc@021d4000 {
				reg = <0x21d4000 0x4000>;
				interrupts = <0x0 0x6d 0x4>;
			};

			audmux@021d8000 {
				compatible = "fsl,imx6q-audmux", "fsl,imx31-audmux";
				reg = <0x21d8000 0x4000>;
				status = "disabled";
			};

			mipi@021dc000 {
				reg = <0x21dc000 0x4000>;
			};

			mipi@021e0000 {
				#address-cells = <0x1>;
				#size-cells = <0x0>;
				reg = <0x21e0000 0x4000>;
				status = "disabled";

				port@0 {
					reg = <0x0>;

					endpoint {
						remote-endpoint = <0x29>;
						linux,phandle = <0x2e>;
						phandle = <0x2e>;
					};
				};

				port@1 {
					reg = <0x1>;

					endpoint {
						remote-endpoint = <0x2a>;
						linux,phandle = <0x32>;
						phandle = <0x32>;
					};
				};
			};

			vdoa@021e4000 {
				reg = <0x21e4000 0x4000>;
				interrupts = <0x0 0x12 0x4>;
			};

			serial@021e8000 {
				compatible = "fsl,imx6q-uart", "fsl,imx21-uart";
				reg = <0x21e8000 0x4000>;
				interrupts = <0x0 0x1b 0x4>;
				clocks = <0x2 0xa0 0x2 0xa1>;
				clock-names = "ipg", "per";
				dmas = <0x5 0x1b 0x4 0x0 0x5 0x1c 0x4 0x0>;
				dma-names = "rx", "tx";
				status = "disabled";
			};

			serial@021ec000 {
				compatible = "fsl,imx6q-uart", "fsl,imx21-uart";
				reg = <0x21ec000 0x4000>;
				interrupts = <0x0 0x1c 0x4>;
				clocks = <0x2 0xa0 0x2 0xa1>;
				clock-names = "ipg", "per";
				dmas = <0x5 0x1d 0x4 0x0 0x5 0x1e 0x4 0x0>;
				dma-names = "rx", "tx";
				status = "okay";
				pinctrl-names = "default";
				pinctrl-0 = <0x2b>;
			};

			serial@021f0000 {
				compatible = "fsl,imx6q-uart", "fsl,imx21-uart";
				reg = <0x21f0000 0x4000>;
				interrupts = <0x0 0x1d 0x4>;
				clocks = <0x2 0xa0 0x2 0xa1>;
				clock-names = "ipg", "per";
				dmas = <0x5 0x1f 0x4 0x0 0x5 0x20 0x4 0x0>;
				dma-names = "rx", "tx";
				status = "okay";
				pinctrl-names = "default";
				pinctrl-0 = <0x2c>;
			};

			serial@021f4000 {
				compatible = "fsl,imx6q-uart", "fsl,imx21-uart";
				reg = <0x21f4000 0x4000>;
				interrupts = <0x0 0x1e 0x4>;
				clocks = <0x2 0xa0 0x2 0xa1>;
				clock-names = "ipg", "per";
				dmas = <0x5 0x21 0x4 0x0 0x5 0x22 0x4 0x0>;
				dma-names = "rx", "tx";
				status = "disabled";
			};

			i2c@021f8000 {
				#address-cells = <0x1>;
				#size-cells = <0x0>;
				compatible = "fsl,imx6q-i2c", "fsl,imx21-i2c";
				reg = <0x21f8000 0x4000>;
				interrupts = <0x0 0x23 0x4>;
				clocks = <0x2 0x74>;
				status = "disabled";
			};
		};

		ipu@02400000 {
			#address-cells = <0x1>;
			#size-cells = <0x0>;
			compatible = "fsl,imx6q-ipu";
			reg = <0x2400000 0x400000>;
			interrupts = <0x0 0x6 0x4 0x0 0x5 0x4>;
			clocks = <0x2 0x82 0x2 0x83 0x2 0x84>;
			clock-names = "bus", "di0", "di1";
			resets = <0x15 0x2>;

			port@0 {
				reg = <0x0>;
			};

			port@1 {
				reg = <0x1>;
			};

			port@2 {
				#address-cells = <0x1>;
				#size-cells = <0x0>;
				reg = <0x2>;
				linux,phandle = <0x38>;
				phandle = <0x38>;

				endpoint@0 {
				};

				endpoint@1 {
					remote-endpoint = <0x2d>;
					linux,phandle = <0x13>;
					phandle = <0x13>;
				};

				endpoint@2 {
					remote-endpoint = <0x2e>;
					linux,phandle = <0x29>;
					phandle = <0x29>;
				};

				endpoint@3 {
					remote-endpoint = <0x2f>;
					linux,phandle = <0xd>;
					phandle = <0xd>;
				};

				endpoint@4 {
					remote-endpoint = <0x30>;
					linux,phandle = <0xf>;
					phandle = <0xf>;
				};
			};

			port@3 {
				#address-cells = <0x1>;
				#size-cells = <0x0>;
				reg = <0x3>;
				linux,phandle = <0x39>;
				phandle = <0x39>;

				endpoint@0 {
				};

				endpoint@1 {
					remote-endpoint = <0x31>;
					linux,phandle = <0x14>;
					phandle = <0x14>;
				};

				endpoint@2 {
					remote-endpoint = <0x32>;
					linux,phandle = <0x2a>;
					phandle = <0x2a>;
				};

				endpoint@3 {
					remote-endpoint = <0x33>;
					linux,phandle = <0xe>;
					phandle = <0xe>;
				};

				endpoint@4 {
					remote-endpoint = <0x34>;
					linux,phandle = <0x10>;
					phandle = <0x10>;
				};
			};
		};

		gpu@00130000 {
			compatible = "fsl,imx6q-gpu";
			reg = <0x130000 0x4000 0x134000 0x4000 0x2204000 0x4000 0x0 0x0>;
			reg-names = "iobase_3d", "iobase_2d", "iobase_vg", "phys_baseaddr";
			interrupts = <0x0 0x9 0x4 0x0 0xa 0x4 0x0 0xb 0x4>;
			interrupt-names = "irq_3d", "irq_2d", "irq_vg";
			clocks = <0x2 0x1a 0x2 0x8f 0x2 0x1b 0x2 0x79 0x2 0x7a 0x2 0x4a>;
			clock-names = "gpu2d_axi_clk", "openvg_axi_clk", "gpu3d_axi_clk", "gpu2d_clk", "gpu3d_clk", "gpu3d_shader_clk";
			resets = <0x15 0x0 0x15 0x3 0x15 0x3>;
			reset-names = "gpu3d", "gpu2d", "gpuvg";
			pu-supply = <0x16>;
			status = "okay";
		};

		sram@00900000 {
			compatible = "mmio-sram";
			reg = <0x900000 0x20000>;
			clocks = <0x2 0x8e>;
		};
	};

	cpus {
		#address-cells = <0x1>;
		#size-cells = <0x0>;

		cpu@0 {
			compatible = "arm,cortex-a9";
			device_type = "cpu";
			reg = <0x0>;
			next-level-cache = <0x35>;
			operating-points = <0xf32a0 0x137478 0xc15c0 0x11edd8 0x60ae0 0x106738>;
			fsl,soc-operating-points = <0xf32a0 0x11edd8 0xc15c0 0x11edd8 0x60ae0 0x11edd8>;
			clock-latency = <0xee6c>;
			clocks = <0x2 0x68 0x2 0x6 0x2 0x10 0x2 0x11 0x2 0xaa>;
			clock-names = "arm", "pll2_pfd2_396m", "step", "pll1_sw", "pll1_sys";
			arm-supply = <0x36>;
			pu-supply = <0x16>;
			soc-supply = <0x37>;
		};

		cpu@1 {
			compatible = "arm,cortex-a9";
			device_type = "cpu";
			reg = <0x1>;
			next-level-cache = <0x35>;
		};
	};

	display-subsystem {
		compatible = "fsl,imx-display-subsystem";
		ports = <0x38 0x39>;
	};

	regulators {
		compatible = "simple-bus";
		#address-cells = <0x1>;
		#size-cells = <0x0>;

		regulator@0 {
			compatible = "regulator-fixed";
			reg = <0x0>;
			regulator-name = "usb_otg_vbus";
			regulator-min-microvolt = <0x4c4b40>;
			regulator-max-microvolt = <0x4c4b40>;
			gpio = <0x7 0xf 0x0>;
			linux,phandle = <0x19>;
			phandle = <0x19>;
		};

		regulator@1 {
			compatible = "regulator-fixed";
			reg = <0x1>;
			regulator-name = "usb_h1_vbus";
			regulator-min-microvolt = <0x4c4b40>;
			regulator-max-microvolt = <0x4c4b40>;
			gpio = <0x22 0x0 0x0>;
			linux,phandle = <0x1c>;
			phandle = <0x1c>;
		};
	};

	leds {
		compatible = "gpio-leds";

		green {
			label = "phyflex:green";
			gpios = <0x22 0x1e 0x0>;
		};

		red {
			label = "phyflex:red";
			gpios = <0x3a 0x1f 0x0>;
		};
	};

	i2c-gpio-0 {
		compatible = "i2c-gpio";
		gpios = <0x7 0xd 0x0 0x7 0xc 0x0>;
		i2c-gpio,delay-us = <0x2>;
		#address-cells = <0x1>;
		#size-cells = <0x0>;
		pinctrl-names = "default";
		pinctrl-0 = <0x3b>;
		status = "okay";
		linux,phandle = <0x12>;
		phandle = <0x12>;
	};

	ir-receiver {
		compatible = "gpio-ir-receiver";
		gpios = <0x27 0x1 0x1>;
		pinctrl-names = "default";
		pinctrl-0 = <0x3c>;
	};

	v4l2_out {
		compatible = "fsl,mxc_v4l2_output";
		status = "okay";
	};

	hdmi_cec {

		hdmicecgrp-1 {
			fsl,pins = <0x134 0x504 0x85c 0x6 0x0 0x1f8b0>;
		};

		hdmicecgrp-2 {
			fsl,pins = <0x260 0x648 0x85c 0x6 0x1 0x1f8b0>;
		};
	};

	caam-sm@00100000 {
		compatible = "fsl,imx6q-caam-sm";
		reg = <0x100000 0x3fff>;
	};

	caam_secvio {
		compatible = "fsl,imx6q-caam-secvio";
		interrupts = <0x0 0x14 0x4>;
		secvio_src = <0x8000001d>;
	};

	caam-snvs@020cc000 {
		compatible = "fsl,imx6q-caam-snvs";
		reg = <0x20cc000 0x4000>;
	};

	caam@2100000 {
		compatible = "fsl,sec-v4.0";
		#address-cells = <0x1>;
		#size-cells = <0x1>;
		reg = <0x2100000 0x40000>;
		ranges = <0x0 0x2100000 0x40000>;
		interrupt-parent = <0x1>;
		clocks = <0x2 0xd5 0x2 0xd6 0x2 0xd7 0x2 0xc4>;
		clock-names = "caam_mem", "caam_aclk", "caam_ipg", "caam_emi_slow";

		jr0@1000 {
			compatible = "fsl,sec-v4.0-job-ring";
			reg = <0x1000 0x1000>;
			interrupt-parent = <0x1>;
			interrupts = <0x0 0x69 0x4>;
		};

		jr1@2000 {
			compatible = "fsl,sec-v4.0-job-ring";
			reg = <0x2000 0x1000>;
			interrupt-parent = <0x1>;
			interrupts = <0x0 0x6a 0x4>;
		};
	};
};
